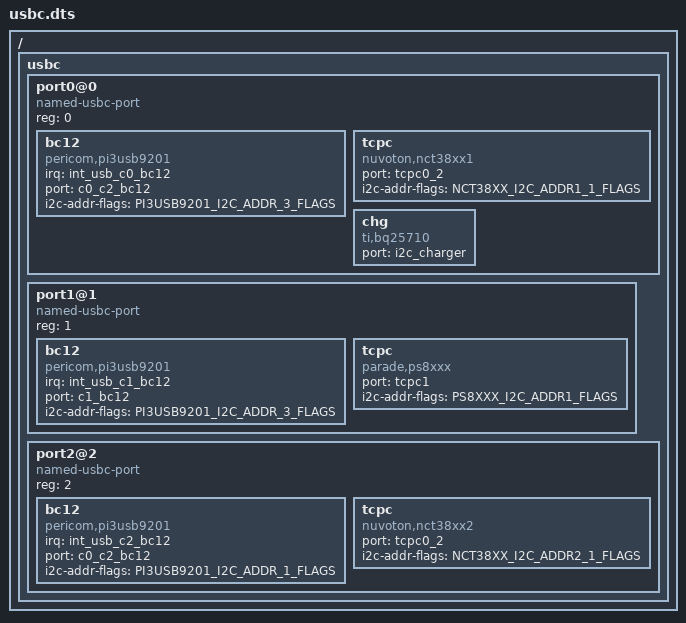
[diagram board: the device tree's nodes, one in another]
/* Copyright 2022 The Chromium OS Authors. All rights reserved.
 * Use of this source code is governed by a BSD-style license that can be
 * found in the LICENSE file.
 */

/ {
	usbc {
		#address-cells = <1>;
		#size-cells = <0>;

		port0@0 {
			compatible = "named-usbc-port";
			reg = <0>;
			bc12 {
				compatible = "pericom,pi3usb9201";
				status = "okay";
				irq = <&int_usb_c0_bc12>;
				port = <&c0_c2_bc12>;
				i2c-addr-flags = "PI3USB9201_I2C_ADDR_3_FLAGS";
			};
			tcpc {
				compatible = "nuvoton,nct38xx1";
                                status = "okay";
                                port = <&tcpc0_2>;
                                i2c-addr-flags = "NCT38XX_I2C_ADDR1_1_FLAGS";
			};
			chg {
				compatible = "ti,bq25710";
				status = "okay";
				port = <&i2c_charger>;
			};
		};

		port1@1 {
			compatible = "named-usbc-port";
			reg = <1>;
			bc12 {
				compatible = "pericom,pi3usb9201";
				status = "okay";
				irq = <&int_usb_c1_bc12>;
				port = <&c1_bc12>;
				i2c-addr-flags = "PI3USB9201_I2C_ADDR_3_FLAGS";
			};
			tcpc {
				compatible = "parade,ps8xxx";
                                status = "okay";
                                port = <&tcpc1>;
                                i2c-addr-flags = "PS8XXX_I2C_ADDR1_FLAGS";
			};
		};

		port2@2 {
			compatible = "named-usbc-port";
			reg = <2>;
			bc12 {
				compatible = "pericom,pi3usb9201";
				status = "okay";
				irq = <&int_usb_c2_bc12>;
				port = <&c0_c2_bc12>;
				i2c-addr-flags = "PI3USB9201_I2C_ADDR_1_FLAGS";
			};
			tcpc {
				compatible = "nuvoton,nct38xx2";
                                status = "okay";
                                port = <&tcpc0_2>;
                                i2c-addr-flags = "NCT38XX_I2C_ADDR2_1_FLAGS";
			};
		};
	};
};
